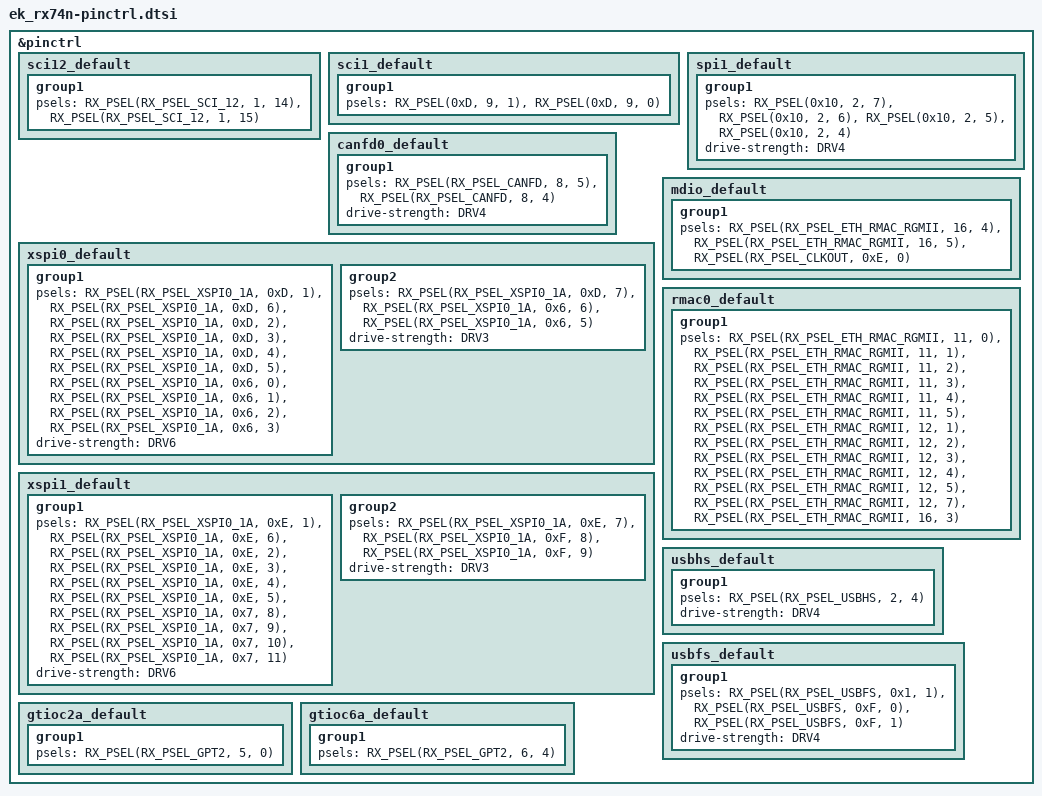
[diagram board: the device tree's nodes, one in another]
/*
 * Copyright (c) 2026 Renesas Electronics Corporation
 * SPDX-License-Identifier: Apache-2.0
 */

&pinctrl {
	sci12_default: sci12_default {
		group1 {
			psels = <RX_PSEL(RX_PSEL_SCI_12, 1, 14)>, /* TX */
				<RX_PSEL(RX_PSEL_SCI_12, 1, 15)>; /* RX */
		};
	};

	sci1_default: sci1_default {
		group1 {
			psels = <RX_PSEL(0xD, 9, 1)>, /* SDA P901*/
				<RX_PSEL(0xD, 9, 0)>; /* SCL P900*/
		};
	};

	spi1_default: spi1_default {
		group1 {
			/* MISO MOSI RSPCK SSL*/
			psels = <RX_PSEL(0x10, 2, 7)>,
				<RX_PSEL(0x10, 2, 6)>,
				<RX_PSEL(0x10, 2, 5)>,
				<RX_PSEL(0x10, 2, 4)>;
			drive-strength = "DRV4";
		};
	};

	canfd0_default: canfd0_default {
		group1 {
			/* CRX0 CTX0 */
			psels = <RX_PSEL(RX_PSEL_CANFD, 8, 5)>,
				<RX_PSEL(RX_PSEL_CANFD, 8, 4)>;
			drive-strength = "DRV4";
		};
	};

	xspi0_default: xspi0_default {
		group1 {
			psels = <RX_PSEL(RX_PSEL_XSPI0_1A, 0xD, 1)>, /* SCLK */
				<RX_PSEL(RX_PSEL_XSPI0_1A, 0xD, 6)>, /* DQS */
				<RX_PSEL(RX_PSEL_XSPI0_1A, 0xD, 2)>, /* SIO0 */
				<RX_PSEL(RX_PSEL_XSPI0_1A, 0xD, 3)>, /* SIO1 */
				<RX_PSEL(RX_PSEL_XSPI0_1A, 0xD, 4)>, /* SIO2 */
				<RX_PSEL(RX_PSEL_XSPI0_1A, 0xD, 5)>, /* SIO3 */
				<RX_PSEL(RX_PSEL_XSPI0_1A, 0x6, 0)>, /* SIO4 */
				<RX_PSEL(RX_PSEL_XSPI0_1A, 0x6, 1)>, /* SIO5 */
				<RX_PSEL(RX_PSEL_XSPI0_1A, 0x6, 2)>, /* SIO6 */
				<RX_PSEL(RX_PSEL_XSPI0_1A, 0x6, 3)>; /* SIO7 */
			drive-strength = "DRV6";
		};

		group2 {
			psels = <RX_PSEL(RX_PSEL_XSPI0_1A, 0xD, 7)>, /* CS0 */
				<RX_PSEL(RX_PSEL_XSPI0_1A, 0x6, 6)>, /* RST */
				<RX_PSEL(RX_PSEL_XSPI0_1A, 0x6, 5)>; /* INT0 */
			drive-strength = "DRV3";
		};
	};

	xspi1_default: xspi1_default {
		group1 {
			psels = <RX_PSEL(RX_PSEL_XSPI0_1A, 0xE, 1)>, /* SCLK */
				<RX_PSEL(RX_PSEL_XSPI0_1A, 0xE, 6)>, /* DQS */
				<RX_PSEL(RX_PSEL_XSPI0_1A, 0xE, 2)>, /* SIO0 */
				<RX_PSEL(RX_PSEL_XSPI0_1A, 0xE, 3)>, /* SIO1 */
				<RX_PSEL(RX_PSEL_XSPI0_1A, 0xE, 4)>, /* SIO2 */
				<RX_PSEL(RX_PSEL_XSPI0_1A, 0xE, 5)>, /* SIO3 */
				<RX_PSEL(RX_PSEL_XSPI0_1A, 0x7, 8)>, /* SIO4 */
				<RX_PSEL(RX_PSEL_XSPI0_1A, 0x7, 9)>, /* SIO5 */
				<RX_PSEL(RX_PSEL_XSPI0_1A, 0x7, 10)>, /* SIO6 */
				<RX_PSEL(RX_PSEL_XSPI0_1A, 0x7, 11)>; /* SIO7 */
			drive-strength = "DRV6";
		};

		group2 {
			psels = <RX_PSEL(RX_PSEL_XSPI0_1A, 0xE, 7)>, /* CS0 */
				<RX_PSEL(RX_PSEL_XSPI0_1A, 0xF, 8)>, /* RST */
				<RX_PSEL(RX_PSEL_XSPI0_1A, 0xF, 9)>; /* INT0 */
			drive-strength = "DRV3";
		};
	};

	mdio_default: mdio_default {
		group1 {
			psels = <RX_PSEL(RX_PSEL_ETH_RMAC_RGMII, 16, 4)>, /* MDC PG04 */
				<RX_PSEL(RX_PSEL_ETH_RMAC_RGMII, 16, 5)>, /* MDIO PG05 */
				<RX_PSEL(RX_PSEL_CLKOUT, 0xE, 0)>; /* PE00 as ETHPHYCLK. */
		};
	};

	rmac0_default: rmac0_default {
		group1 {
			psels = <RX_PSEL(RX_PSEL_ETH_RMAC_RGMII, 11, 0)>, /* RXD0 PB00 */
				<RX_PSEL(RX_PSEL_ETH_RMAC_RGMII, 11, 1)>, /* RXD1 PB01 */
				<RX_PSEL(RX_PSEL_ETH_RMAC_RGMII, 11, 2)>, /* RXD2 PB02 */
				<RX_PSEL(RX_PSEL_ETH_RMAC_RGMII, 11, 3)>, /* RXD3 PB03 */
				<RX_PSEL(RX_PSEL_ETH_RMAC_RGMII, 11, 4)>, /* RXC PB04 */
				<RX_PSEL(RX_PSEL_ETH_RMAC_RGMII, 11, 5)>, /* RX_CTL PB05 */
				<RX_PSEL(RX_PSEL_ETH_RMAC_RGMII, 12, 1)>, /* TXD0 PC01 */
				<RX_PSEL(RX_PSEL_ETH_RMAC_RGMII, 12, 2)>, /* TXD1 PC02 */
				<RX_PSEL(RX_PSEL_ETH_RMAC_RGMII, 12, 3)>, /* TXD2 PC03 */
				<RX_PSEL(RX_PSEL_ETH_RMAC_RGMII, 12, 4)>, /* TXD3 PC04 */
				<RX_PSEL(RX_PSEL_ETH_RMAC_RGMII, 12, 5)>, /* TX_CTL PC05 */
				<RX_PSEL(RX_PSEL_ETH_RMAC_RGMII, 12, 7)>, /* TXC PC07 */
				<RX_PSEL(RX_PSEL_ETH_RMAC_RGMII, 16, 3)>; /* MDINT PG03 */
		};
	};

	usbhs_default: usbhs_default {
		group1 {
			psels = <RX_PSEL(RX_PSEL_USBHS, 2, 4)>; /* VBUS-DS */
			drive-strength = "DRV4";
		};
	};

	usbfs_default: usbfs_default {
		group1 {
			psels = <RX_PSEL(RX_PSEL_USBFS, 0x1, 1)>, /* VBUS */
				<RX_PSEL(RX_PSEL_USBFS, 0xF, 0)>, /* D+ */
				<RX_PSEL(RX_PSEL_USBFS, 0xF, 1)>; /* D- */
			drive-strength = "DRV4";
		};
	};

	gtioc2a_default: gtioc2a_default {
		group1 {
			psels = <RX_PSEL(RX_PSEL_GPT2, 5, 0)>; /* GTIOC2A */
		};
	};

	gtioc6a_default: gtioc6a_default {
		group1 {
			psels = <RX_PSEL(RX_PSEL_GPT2, 6, 4)>; /* GTIOC6A */
		};
	};
};
